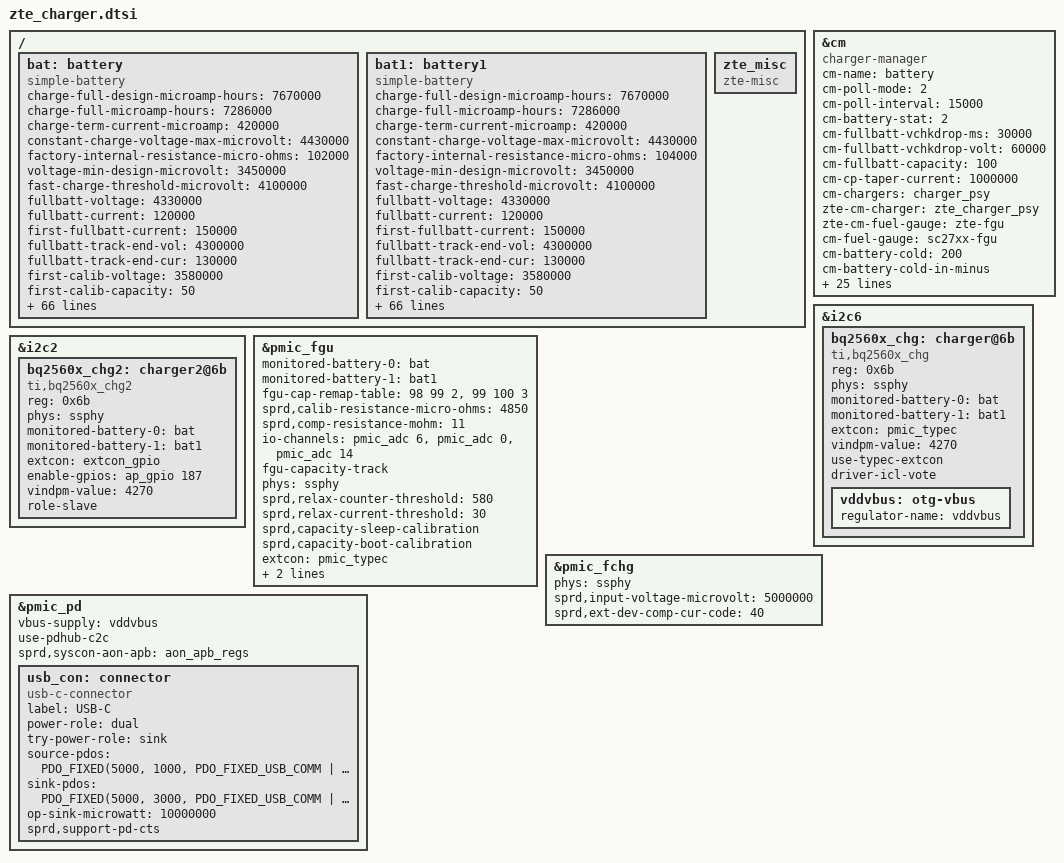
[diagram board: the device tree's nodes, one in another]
#include <dt-bindings/usb/pd.h>


/ {
	bat: battery {
		compatible = "simple-battery";
		status = "okay";
		charge-full-design-microamp-hours = <5000000>;
		/*Minimum Capacity 4870*0.9 = 4383 4870*0.94 = 4558 4870*0.95 = 4626 4870*0.96 = 4675,4870*0.98 = 4772  we use *0.98 */
		charge-full-microamp-hours = <4772000>;
		charge-term-current-microamp = <420000>;
		constant-charge-voltage-max-microvolt = <4400000>;
		factory-internal-resistance-micro-ohms = <225000>;
		voltage-min-design-microvolt = <3450000>;

		fast-charge-threshold-microvolt = <4100000>;
		fullbatt-voltage = <4300000>;
		fullbatt-current = <120000>;
		first-fullbatt-current = <150000>;
		fullbatt-track-end-vol = <4295000>;
		fullbatt-track-end-cur = <130000>;
		first-calib-voltage = <3580000>;
		first-calib-capacity = <50>;

		ir-cv-offset-microvolt = <100000>;
		ir-rc-micro-ohms = <20000>;
		ir-us-upper-limit-microvolt = <4500000>;

		batt-id-list = <300 10 390 20>;  /* kohm, scud / ningde / tianmao /guanyu*/
		ocv-capacity-celsius = <20>;
		ocv-capacity-table-0 = <4374000 100>, <4308000 95>, <4250000 90>,
					<4193000 85>, <4139000 80>, <4086000 75>,
					<4037000 70>, <3992000 65>, <3951000 60>,
					<3896000 55>, <3860000 50>, <3836000 45>,
					<3814000 40>, <3797000 35>, <3784000 30>,
					<3767000 25>, <3749000 20>, <3726000 15>,
					<3697000 10>, <3683000 5>, <3400000 0>;
		/* NTC 100k, Vref 1850mV, R pull-up 110K, R pull-down 1000k */
		voltage-temp-table = <1568441 750>, <1534549 800>, <1515014 850>,
					<1475819 900>, <1402274 950>, <1334550 1000>,
					<1222195 1050>, <1131821 1100>, <1035662 1150>,
					<936426 1200>, <837104 1250>, <740441 1300>,
					<648801 1350>, <563916 1400>, <486937 1450>,
					<418193 1500>, <357806 1550>, <305304 1600>,
					<260067 1650>, <221438 1700>, <188468 1750>;
		capacity-temp-table = <25 100>, <10 100>, <0 97>, <(-10) 89>, <(-20) 57>;
		resistance-temp-table = <25 100>, <10 332>, <0 507>, <(-10) 569>, <(-20) 675>;
		charge-sdp-current-microamp = <700000 500000>;
		charge-dcp-current-microamp = <2000000 3000000>;
		charge-cdp-current-microamp = <1500000 1500000>;
		charge-unknown-current-microamp = <1000000 1000000>;
		charge-fchg-current-microamp = <3400000 2000000>;
		charge-flash-current-microamp = <3400000 2700000>;

		cap-calib-energy-density-ocv-table = <3350000 3800000>, <4150000 4350000>;
		cap-track-energy-density-ocv-table = <3400000 3722000>;

		dcp-jeita-temp-table = <1000 1030 0 4400000>,
					<1050 1080 1400000 4400000>,
					<1100 1180 1400000 4400000>,
					<1450 1420 3400000 4400000>,
					<1550 1520 2400000 4100000>;
		sdp-jeita-temp-table = <1000 1030 0 4400000>,
					<1050 1080 1400000 4400000>,
					<1100 1180 1400000 4400000>,
					<1450 1420 3400000 4400000>,
					<1550 1520 2400000 4100000>;
		cdp-jeita-temp-table = <1000 1030 0 4400000>,
					<1050 1080 1400000 4400000>,
					<1100 1180 1400000 4400000>,
					<1450 1420 3400000 4400000>,
					<1550 1520 2400000 4100000>;
		unknown-jeita-temp-table = <1000 1030 0 4400000>,
					<1050 1080 1400000 4400000>,
					<1100 1180 1400000 4400000>,
					<1450 1420 3400000 4400000>,
					<1550 1520 2400000 4100000>;
		fchg-jeita-temp-table = <1000 1030 0 4400000>,
					<1050 1080 1400000 4400000>,
					<1100 1180 1400000 4400000>,
					<1450 1420 3400000 4400000>,
					<1550 1520 2400000 4100000>;
		flash-jeita-temp-table = <1000 1030 0 4400000>,
					<1050 1080 1400000 4400000>,
					<1100 1180 1400000 4400000>,
					<1450 1420 3400000 4400000>,
					<1550 1520 2400000 4100000>;
	};

	bat1: battery1 {
		compatible = "simple-battery";
		status = "okay";
		charge-full-design-microamp-hours = <5000000>;
		/*Minimum Capacity 4870*0.9 = 4383 4870*0.94 = 4558 4870*0.95 = 4626 4870*0.96 = 4675,4870*0.98 = 4772  we use *0.98 */
		charge-full-microamp-hours = <4772000>;
		charge-term-current-microamp = <420000>;
		constant-charge-voltage-max-microvolt = <4400000>;
		factory-internal-resistance-micro-ohms = <225000>;
		voltage-min-design-microvolt = <3450000>;

		fast-charge-threshold-microvolt = <4100000>;
		fullbatt-voltage = <4300000>;
		fullbatt-current = <120000>;
		first-fullbatt-current = <150000>;
		fullbatt-track-end-vol = <4295000>;
		fullbatt-track-end-cur = <130000>;
		first-calib-voltage = <3580000>;
		first-calib-capacity = <50>;

		ir-cv-offset-microvolt = <100000>;
		ir-rc-micro-ohms = <20000>;
		ir-us-upper-limit-microvolt = <4500000>;

		batt-id-list = <300 10 390 20>;  /* kohm, scud / ningde / tianmao /guanyu*/
		ocv-capacity-celsius = <20>;
		ocv-capacity-table-0 = <4374000 100>, <4308000 95>, <4250000 90>,
					<4193000 85>, <4139000 80>, <4086000 75>,
					<4037000 70>, <3992000 65>, <3951000 60>,
					<3896000 55>, <3860000 50>, <3836000 45>,
					<3814000 40>, <3797000 35>, <3784000 30>,
					<3767000 25>, <3749000 20>, <3726000 15>,
					<3697000 10>, <3683000 5>, <3400000 0>;
		/* NTC 100k, Vref 1850mV, R pull-up 110K, R pull-down 1000k */
		voltage-temp-table = <1568441 750>, <1534549 800>, <1515014 850>,
					<1475819 900>, <1402274 950>, <1334550 1000>,
					<1222195 1050>, <1131821 1100>, <1035662 1150>,
					<936426 1200>, <837104 1250>, <740441 1300>,
					<648801 1350>, <563916 1400>, <486937 1450>,
					<418193 1500>, <357806 1550>, <305304 1600>,
					<260067 1650>, <221438 1700>, <188468 1750>;
		capacity-temp-table = <25 100>, <10 100>, <0 97>, <(-10) 89>, <(-20) 57>;
		resistance-temp-table = <25 100>, <10 332>, <0 507>, <(-10) 569>, <(-20) 675>;
		charge-sdp-current-microamp = <700000 500000>;
		charge-dcp-current-microamp = <2000000 3000000>;
		charge-cdp-current-microamp = <1500000 1500000>;
		charge-unknown-current-microamp = <1000000 1000000>;
		charge-fchg-current-microamp = <3400000 2000000>;
		charge-flash-current-microamp = <3400000 2700000>;

		cap-calib-energy-density-ocv-table = <3350000 3800000>, <4150000 4350000>;
		cap-track-energy-density-ocv-table = <3400000 3722000>;

		dcp-jeita-temp-table = <1000 1030 0 4400000>,
					<1050 1080 1400000 4400000>,
					<1100 1180 1400000 4400000>,
					<1450 1420 3400000 4400000>,
					<1550 1520 2400000 4100000>;
		sdp-jeita-temp-table = <1000 1030 0 4400000>,
					<1050 1080 1400000 4400000>,
					<1100 1180 1400000 4400000>,
					<1450 1420 3400000 4400000>,
					<1550 1520 2400000 4100000>;
		cdp-jeita-temp-table = <1000 1030 0 4400000>,
					<1050 1080 1400000 4400000>,
					<1100 1180 1400000 4400000>,
					<1450 1420 3400000 4400000>,
					<1550 1520 2400000 4100000>;
		unknown-jeita-temp-table = <1000 1030 0 4400000>,
					<1050 1080 1400000 4400000>,
					<1100 1180 1400000 4400000>,
					<1450 1420 3400000 4400000>,
					<1550 1520 2400000 4100000>;
		fchg-jeita-temp-table = <1000 1030 0 4400000>,
					<1050 1080 1400000 4400000>,
					<1100 1180 1400000 4400000>,
					<1450 1420 3400000 4400000>,
					<1550 1520 2400000 4100000>;
		flash-jeita-temp-table = <1000 1030 0 4400000>,
					<1050 1080 1400000 4400000>,
					<1100 1180 1400000 4400000>,
					<1450 1420 3400000 4400000>,
					<1550 1520 2400000 4100000>;
	};
};

&bat {
	charge-term-current-microamp = <420000>;
	constant-charge-voltage-max-microvolt = <4430000>;
	constant-charge-current-max-microamp = <5300000>;
	factory-internal-resistance-micro-ohms = <102000>;
	voltage-min-design-microvolt = <3450000>;
	fast-charge-threshold-microvolt = <4100000>;
	fullbatt-voltage = <4330000>;
	fullbatt-current = <120000>;
	fullbatt-track-end-vol = <4300000>;
	fullbatt-track-end-cur = <130000>;
	first-calib-voltage = <3580000>;
	first-calib-capacity = <50>;

	ir-cv-offset-microvolt = <100000>;
	ir-rc-micro-ohms = <20000>;
	ir-us-upper-limit-microvolt = <4500000>;

	batt-id-list = <47 121>;  /*kohm, fenghua, haopeng*/
	charge-full-design-microamp-hours = <7670000>;
	/*7670*0.94 = 7209 4520*0.95 = 7286 4520*0.96 = 7363 4520*0.97 = 7439, we use *0.95 */
	charge-full-microamp-hours = <7286000>;

	ocv-capacity-celsius = <25>;
	ocv-capacity-table-0 = <4385000 100>, <4327000 95>, <4270000 90>,
				<4211000 85>, <4154000 80>, <4099000 75>,
				<4049000 70>, <4002000 65>, <3959000 60>,
				<3898000 55>, <3863000 50>, <3837000 45>,
				<3816000 40>, <3799000 35>, <3785000 30>,
				<3764000 25>, <3743000 20>, <3718000 15>,
				<3690000 10>, <3679000 5>, <3400000 0>;
	/* NTC 100k, Vref 1850mV, R pull-up 110K, R pull-down 1000k */
	voltage-temp-table = <1591473 750>, <1555286 800>, <1512176 850>,
				<1459276 900>, <1395886 950>, <1322179 1000>,
				<1238711 1050>, <1147116 1100>, <1049658 1150>,
				<949081 1200>, <848416 1250>, <750447 1300>,
				<657569 1350>, <571537 1400>, <493518 1450>,
				<423845 1500>, <362641 1550>, <309430 1600>,
				<263582 1650>, <221438 1700>, <188468 1750>;
	capacity-temp-table = <25 100>, <10 100>, <0 98>, <(-10) 92>, <(-20) 77>;
	resistance-temp-table = <25 100>, <10 147>, <0 859>, <(-10) 1134>, <(-20) 1287>;

	charge-sdp-current-microamp = <500000 500000>;
	charge-dcp-current-microamp = <5300000 2000000>;
	charge-cdp-current-microamp = <5300000 1500000>;
	charge-unknown-current-microamp = <1000000 1000000>;
	charge-fchg-current-microamp = <5300000 2000000>;
	charge-flash-current-microamp = <5300000 2000000>;

	dcp-jeita-temp-table = <1000 1030 0 4430000>,
				<1100 1080 1500000 4430000>,
				<1150 1180 1500000 4430000>,
				<1450 1420 5300000 4430000>,
				<1550 1520 3800000 4100000>;
	sdp-jeita-temp-table = <1000 1030 0 4430000>,
				<1100 1080 1500000 4430000>,
				<1150 1180 1500000 4430000>,
				<1450 1420 5300000 4430000>,
				<1550 1520 3800000 4100000>;
	cdp-jeita-temp-table = <1000 1030 0 4430000>,
				<1100 1080 1500000 4430000>,
				<1150 1180 1500000 4430000>,
				<1450 1420 5300000 4430000>,
				<1550 1520 3800000 4100000>;
	unknown-jeita-temp-table = <1000 1030 0 4430000>,
				<1100 1080 1500000 4430000>,
				<1150 1180 1500000 4430000>,
				<1450 1420 5300000 4430000>,
				<1550 1520 3800000 4100000>;

	fchg-jeita-temp-table = <1000 1030 0 4430000>,
				<1100 1080 1500000 4430000>,
				<1150 1180 1500000 4430000>,
				<1450 1420 5300000 4430000>,
				<1550 1520 3800000 4100000>;
	flash-jeita-temp-table = <1000 1030 0 4430000>,
				<1100 1080 1500000 4430000>,
				<1150 1180 1500000 4430000>,
				<1450 1420 5300000 4430000>,
				<1550 1520 3800000 4100000>;
};

&bat1 {
	charge-term-current-microamp = <420000>;
	constant-charge-voltage-max-microvolt = <4430000>;
	constant-charge-current-max-microamp = <5300000>;
	factory-internal-resistance-micro-ohms = <104000>;
	voltage-min-design-microvolt = <3450000>;
	fast-charge-threshold-microvolt = <4100000>;
	fullbatt-voltage = <4330000>;
	fullbatt-current = <120000>;
	fullbatt-track-end-vol = <4300000>;
	fullbatt-track-end-cur = <130000>;
	first-calib-voltage = <3580000>;
	first-calib-capacity = <50>;

	ir-cv-offset-microvolt = <100000>;
	ir-rc-micro-ohms = <20000>;
	ir-us-upper-limit-microvolt = <4500000>;

	ocv-capacity-celsius = <25>;
	batt-id-list = <47 121>;  /*kohm, fenghua, haopeng*/
	charge-full-design-microamp-hours = <7670000>;
	/*7670*0.94 = 7209 4520*0.95 = 7286 4520*0.96 = 7363 4520*0.97 = 7439, we use *0.95 */
	charge-full-microamp-hours = <7286000>;

	ocv-capacity-table-0 = <4383000 100>, <4329000 95>, <4272000 90>,
				<4214000 85>, <4157000 80>, <4103000 75>,
				<4052000 70>, <4005000 65>, <3963000 60>,
				<3900000 55>, <3866000 50>, <3840000 45>,
				<3819000 40>, <3801000 35>, <3786000 30>,
				<3763000 25>, <3743000 20>, <3718000 15>,
				<3690000 10>, <3679000 5>, <3400000 0>;
	/* NTC 100k, Vref 1850mV, R pull-up 110K, R pull-down 1000k */
	voltage-temp-table = <1591473 750>, <1555286 800>, <1512176 850>,
				<1459276 900>, <1395886 950>, <1322179 1000>,
				<1238711 1050>, <1147116 1100>, <1049658 1150>,
				<949081 1200>, <848416 1250>, <750447 1300>,
				<657569 1350>, <571537 1400>, <493518 1450>,
				<423845 1500>, <362641 1550>, <309430 1600>,
				<263582 1650>, <221438 1700>, <188468 1750>;
	capacity-temp-table = <25 100>, <10 99>, <0 99>, <(-10) 95>, <(-20) 81>;
	resistance-temp-table = <25 100>, <10 146>, <0 721>, <(-10) 1073>, <(-20) 1249>;

	charge-sdp-current-microamp = <500000 500000>;
	charge-dcp-current-microamp = <5300000 2000000>;
	charge-cdp-current-microamp = <5300000 1500000>;
	charge-unknown-current-microamp = <1000000 1000000>;
	charge-fchg-current-microamp = <5300000 2000000>;
	charge-flash-current-microamp = <5300000 2000000>;

	dcp-jeita-temp-table = <1000 1030 0 4430000>,
				<1100 1080 1500000 4430000>,
				<1150 1180 1500000 4430000>,
				<1450 1420 5300000 4430000>,
				<1550 1520 3800000 4100000>;
	sdp-jeita-temp-table = <1000 1030 0 4430000>,
				<1100 1080 1500000 4430000>,
				<1150 1180 1500000 4430000>,
				<1450 1420 5300000 4430000>,
				<1550 1520 3800000 4100000>;
	cdp-jeita-temp-table = <1000 1030 0 4430000>,
				<1100 1080 1500000 4430000>,
				<1150 1180 1500000 4430000>,
				<1450 1420 5300000 4430000>,
				<1550 1520 3800000 4100000>;
	unknown-jeita-temp-table = <1000 1030 0 4430000>,
				<1100 1080 1500000 4430000>,
				<1150 1180 1500000 4430000>,
				<1450 1420 5300000 4430000>,
				<1550 1520 3800000 4100000>;

	fchg-jeita-temp-table = <1000 1030 0 4430000>,
				<1100 1080 1500000 4430000>,
				<1150 1180 1500000 4430000>,
				<1450 1420 5300000 4430000>,
				<1550 1520 3800000 4100000>;
	flash-jeita-temp-table = <1000 1030 0 4430000>,
				<1100 1080 1500000 4430000>,
				<1150 1180 1500000 4430000>,
				<1450 1420 5300000 4430000>,
				<1550 1520 3800000 4100000>;
};

&cm {
	compatible = "charger-manager";
	status = "okay";
	cm-name = "battery";
	cm-poll-mode = <2>;
	cm-poll-interval = <15000>;
	cm-battery-stat = <2>;

	cm-fullbatt-vchkdrop-ms = <30000>;
	cm-fullbatt-vchkdrop-volt = <60000>;
	cm-fullbatt-capacity = <100>;
	/*Charge pump target charge current*/
	cm-cp-taper-current = <1000000>;

	cm-chargers = "charger_psy";
	zte-cm-charger = "zte_charger_psy";
	zte-cm-fuel-gauge = "zte-fgu";

	cm-fuel-gauge = "sc27xx-fgu";

	/* in deci centigrade */
	cm-battery-cold = <200>;
	cm-battery-cold-in-minus;
	cm-battery-hot = <800>;
	cm-battery-temp-diff = <100>;

	/* Allow charging for 6hr */
	cm-charging-max = <21600000>;
	/* recovery charging after stop charging 45min */
	cm-discharging-max = <2700000>;

	/* the interval to feed charger watchdog */
	cm-wdt-interval = <60>;

	/* drop voltage in microVolts to allow shutdown */
	cm-shutdown-voltage = <3100000>;

	/* when 99% of the time is exceeded, it will be forced to 100% */
	cm-tickle-time-out = <1500>;

	/* how much time to allow capacity change */
	cm-one-cap-time = <30>;

	/* because kernel not load thermal-gerneric-adc.ko in charger mode, then battery uevent can't broadcast to ztecharger */
	/* cm-thermal-zone = "board-thmzone"; */

	/* when the safe charging voltage is exceeded, stop charging */
	cm-charge-voltage-max = <6500000>;
	cm-fast-charge-voltage-max = <10500000>;
	cm-flash-charge-voltage-max = <12000000>;
	/* drop voltage in microVolts to restart charging */
	cm-charge-voltage-drop = <700000>;
	cm-fast-charge-voltage-drop = <700000>;
	cm-flash-charge-voltage-drop = <1000000>;

	/* sprd_fchg parameter */
	sprd,support-fchg;
	sprd,support-sfcp;
	sprd,pd-fixed-max-microwatt = <30000000>;

	monitored-battery-0 = <&bat>;
	monitored-battery-1 = <&bat1>;
	cm-capacity-track;
	cm-keep-awake;

	phys = <&ssphy>;
	pd-extcon-enable;
	extcon = <&pmic_typec>, <&pmic_pd>;
	use-typec-extcon;
};

/ {
	zte_misc: zte_misc {
		status = "okay";
		compatible = "zte-misc";
	};
};

&i2c6 {
	#address-cells = <1>;
	#size-cells = <0>;

	status = "okay";
	bq2560x_chg: charger@6b {
		compatible = "ti,bq2560x_chg";
		reg = <0x6b>;
		phys = <&ssphy>;
		monitored-battery-0 = <&bat>;
		monitored-battery-1 = <&bat1>;
		extcon = <&pmic_typec>;
		vindpm-value = <4270>;
		use-typec-extcon;
		driver-icl-vote;
		vddvbus:otg-vbus {
			regulator-name = "vddvbus";
		};
	};
};

&i2c2 {
	status = "okay";
	bq2560x_chg2: charger2@6b {
		compatible = "ti,bq2560x_chg2";
		reg = <0x6b>;
		phys = <&ssphy>;
		monitored-battery-0 = <&bat>;
		monitored-battery-1 = <&bat1>;
		extcon = <&extcon_gpio>;
		enable-gpios = <&ap_gpio 187 0>;
		vindpm-value = <4270>;
		role-slave;
	};
};

&pmic_fgu {
	monitored-battery-0 = <&bat>;
	monitored-battery-1 = <&bat1>;
	fgu-cap-remap-table = <98 99 2>, <99 100 3>;
	sprd,calib-resistance-micro-ohms = <4850>;
	sprd,comp-resistance-mohm = <11>;
	io-channels = <&pmic_adc 6>, <&pmic_adc 0>, <&pmic_adc 14>;
	io-channel-names = "adc-batt-id", "bat-temp", "charge-vol";
	fgu-capacity-track;
	phys = <&ssphy>;

	sprd,relax-counter-threshold = <580>;
	sprd,relax-current-threshold = <30>;
	sprd,capacity-sleep-calibration;

	sprd,capacity-boot-calibration;
	extcon = <&pmic_typec>;
	sprd,zte-low-temp-algo;
	use-typec-extcon;
	extcon = <&pmic_typec>;
};

&pmic_fchg {
	status = "okay";
	phys = <&ssphy>;
	sprd,input-voltage-microvolt = <5000000>;
	sprd,ext-dev-comp-cur-code = <40>;
};

&pmic_pd {
	status = "okay";
	vbus-supply = <&vddvbus>;
	use-pdhub-c2c;
	sprd,syscon-aon-apb = <&aon_apb_regs>;
	usb_con: connector {
		compatible = "usb-c-connector";
		label = "USB-C";
		power-role = "dual";
		try-power-role = "sink";
		source-pdos = <PDO_FIXED(5000, 1000, PDO_FIXED_USB_COMM | PDO_FIXED_SUSPEND |
				PDO_FIXED_DUAL_ROLE | PDO_FIXED_DATA_SWAP)>;
		sink-pdos = <PDO_FIXED(5000, 3000, PDO_FIXED_USB_COMM | PDO_FIXED_DUAL_ROLE |
				PDO_FIXED_DATA_SWAP)>;
		op-sink-microwatt = <10000000>;

		sprd,support-pd-cts;
	};
};

#include "../bat_setting/battery_protect_policy_080509200178_48.dtsi"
